# ESP32-C3 register map
Vendor: ESPRESSIF SYSTEMS (SHANGHAI) CO., LTD.; Series: ESP32 C-Series; File version: 19
CPU: RV32IMC r0p0, little endian, no MPU, no FPU, 0 interrupt priority bits
Address unit: 32 bits
Registers are 32-bit, read-write, reset 0x0 unless marked. A register's access mark holds for its fields unless they carry their own. Offsets are from the block's base; [hi:lo] are bit positions; {n}, {i} and the like mark numbered series.

## SHA — SHA (Secure Hash Algorithm) Accelerator
Base 0x6003B000
0x00 MODE — Initial configuration register.
  [2:0] MODE — Sha mode.
0x04 T_STRING — SHA 512/t configuration register 0.
  [31:0] T_STRING — Sha t_string (used if and only if mode == SHA_512/t).
0x08 T_LENGTH — SHA 512/t configuration register 1.
  [5:0] T_LENGTH — Sha t_length (used if and only if mode == SHA_512/t).
0x0C DMA_BLOCK_NUM — DMA configuration register 0.
  [5:0] DMA_BLOCK_NUM — Dma-sha block number.
0x10 START ro — Typical SHA configuration register 0.
  [31:1] START — Reserved.
0x14 CONTINUE ro — Typical SHA configuration register 1.
  [31:1] CONTINUE — Reserved.
0x18 BUSY ro
  [0] STATE — Sha busy state. 1'b0: idle. 1'b1: busy.
0x1C DMA_START wo — DMA configuration register 1.
  [0] DMA_START — Start dma-sha.
0x20 DMA_CONTINUE wo — DMA configuration register 2.
  [0] DMA_CONTINUE — Continue dma-sha.
0x24 CLEAR_IRQ wo — Interrupt clear register.
  [0] CLEAR_INTERRUPT — Clear sha interrupt.
0x28 IRQ_ENA — Interrupt enable register.
  [0] INTERRUPT_ENA — Sha interrupt enable register. 1'b0: disable(default). 1'b1: enable.
0x2C DATE reset 0x20200616
  [29:0] DATE — Sha date information/ sha version information.
{0x40+i} H_MEM[{i}] (i=0..63) 8-bit access not given — Sha H memory which contains intermediate hash or finial hash.
{0x80+i} M_MEM[{i}] (i=0..63) 8-bit access not given — Sha M memory which contains message.

## SYSTIMER — System Timer
Base 0x60023000
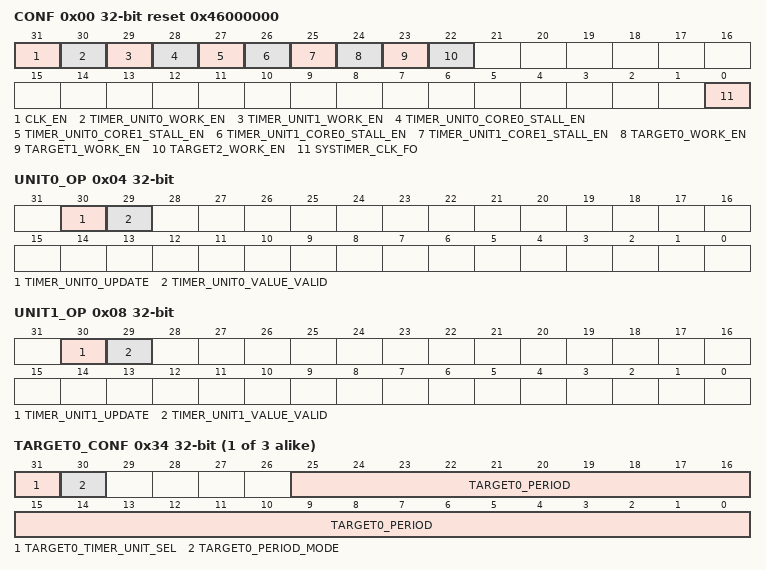
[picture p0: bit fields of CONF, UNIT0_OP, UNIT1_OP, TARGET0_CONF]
0x00 CONF reset 0x46000000 — SYSTIMER_CONF.
  [31] CLK_EN — register file clk gating
  [30] TIMER_UNIT0_WORK_EN — timer unit0 work enable
  [29] TIMER_UNIT1_WORK_EN — timer unit1 work enable
  [28] TIMER_UNIT0_CORE0_STALL_EN — If timer unit0 is stalled when core0 stalled
  [27] TIMER_UNIT0_CORE1_STALL_EN — If timer unit0 is stalled when core1 stalled
  [26] TIMER_UNIT1_CORE0_STALL_EN — If timer unit1 is stalled when core0 stalled
  [25] TIMER_UNIT1_CORE1_STALL_EN — If timer unit1 is stalled when core1 stalled
  [24] TARGET0_WORK_EN — target0 work enable
  [23] TARGET1_WORK_EN — target1 work enable
  [22] TARGET2_WORK_EN — target2 work enable
  [0] SYSTIMER_CLK_FO — systimer clock force on
0x04 UNIT0_OP access per field — SYSTIMER_UNIT0_OP.
  [30] TIMER_UNIT0_UPDATE wo — update timer_unit0
  [29] TIMER_UNIT0_VALUE_VALID ro — reg_timer_unit0_value_valid
0x08 UNIT1_OP access per field — SYSTIMER_UNIT1_OP.
  [30] TIMER_UNIT1_UPDATE wo — update timer unit1
  [29] TIMER_UNIT1_VALUE_VALID ro — timer value is sync and valid
0x0C UNIT0_LOAD_HI — SYSTIMER_UNIT0_LOAD_HI.
  [19:0] TIMER_UNIT0_LOAD_HI — timer unit0 load high 32 bit
0x10 UNIT0_LOAD_LO — SYSTIMER_UNIT0_LOAD_LO.
  [31:0] TIMER_UNIT0_LOAD_LO — timer unit0 load low 32 bit
0x14 UNIT1_LOAD_HI — SYSTIMER_UNIT1_LOAD_HI.
  [19:0] TIMER_UNIT1_LOAD_HI — timer unit1 load high 32 bit
0x18 UNIT1_LOAD_LO — SYSTIMER_UNIT1_LOAD_LO.
  [31:0] TIMER_UNIT1_LOAD_LO — timer unit1 load low 32 bit
{0x1C+8i} TARGET{i}_HI (i=0..2) — SYSTIMER_TARGET{i}_HI.
  [19:0] TIMER_TARGET{i}_HI — timer taget{i} high 32 bit
{0x20+8i} TARGET{i}_LO (i=0..2) — SYSTIMER_TARGET{i}_LO.
  [31:0] TIMER_TARGET{i}_LO — timer taget{i} low 32 bit
{0x34+4i} TARGET{i}_CONF (i=0..2) — SYSTIMER_TARGET{i}_CONF.
  [31] TARGET{i}_TIMER_UNIT_SEL — select which unit to compare
  [30] TARGET{i}_PERIOD_MODE — Set target{i} to period mode
  [25:0] TARGET{i}_PERIOD
0x40 UNIT0_VALUE_HI ro — SYSTIMER_UNIT0_VALUE_HI.
  [19:0] TIMER_UNIT0_VALUE_HI — timer read value high 32bit
0x44 UNIT0_VALUE_LO ro — SYSTIMER_UNIT0_VALUE_LO.
  [31:0] TIMER_UNIT0_VALUE_LO — timer read value low 32bit
0x48 UNIT1_VALUE_HI ro — SYSTIMER_UNIT1_VALUE_HI.
  [19:0] TIMER_UNIT1_VALUE_HI — timer read value high 32bit
0x4C UNIT1_VALUE_LO ro — SYSTIMER_UNIT1_VALUE_LO.
  [31:0] TIMER_UNIT1_VALUE_LO — timer read value low 32bit
{0x50+4i} COMP{i}_LOAD wo (i=0..2) — SYSTIMER_COMP{i}_LOAD.
  [0] TIMER_COMP{i}_LOAD — timer comp{i} load value
0x5C UNIT0_LOAD wo — SYSTIMER_UNIT0_LOAD.
  [0] TIMER_UNIT0_LOAD — timer unit0 load value
0x60 UNIT1_LOAD wo — SYSTIMER_UNIT1_LOAD.
  [0] TIMER_UNIT1_LOAD — timer unit1 load value
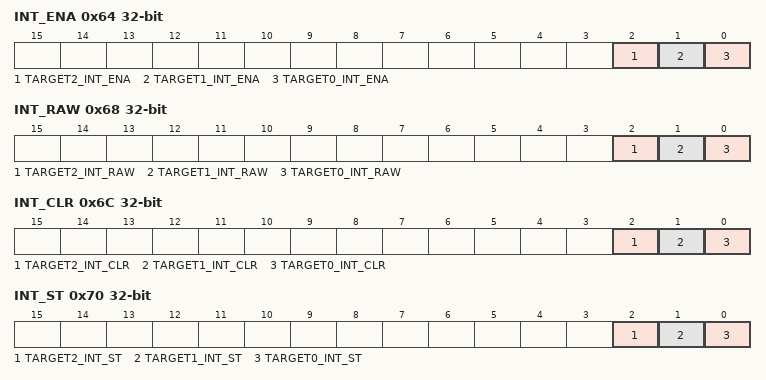
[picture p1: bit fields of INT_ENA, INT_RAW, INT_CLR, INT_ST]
0x64 INT_ENA — SYSTIMER_INT_ENA.
  [2] TARGET2_INT_ENA — interupt2 enable
  [1] TARGET1_INT_ENA — interupt1 enable
  [0] TARGET0_INT_ENA — interupt0 enable
0x68 INT_RAW — SYSTIMER_INT_RAW.
  [2] TARGET2_INT_RAW — interupt2 raw
  [1] TARGET1_INT_RAW — interupt1 raw
  [0] TARGET0_INT_RAW — interupt0 raw
0x6C INT_CLR wo — SYSTIMER_INT_CLR.
  [2] TARGET2_INT_CLR — interupt2 clear
  [1] TARGET1_INT_CLR — interupt1 clear
  [0] TARGET0_INT_CLR — interupt0 clear
0x70 INT_ST ro — SYSTIMER_INT_ST.
  [2] TARGET2_INT_ST — reg_target2_int_st
  [1] TARGET1_INT_ST — reg_target1_int_st
  [0] TARGET0_INT_ST — reg_target0_int_st
0xFC DATE reset 0x2006171 — SYSTIMER_DATE.
  [31:0] DATE — reg_date
